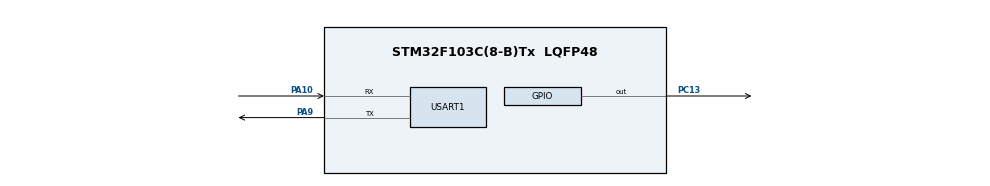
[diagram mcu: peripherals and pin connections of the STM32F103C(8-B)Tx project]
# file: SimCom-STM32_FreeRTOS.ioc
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Dma.Request0=USART1_TX
Dma.USART1_TX.0.Direction=DMA_MEMORY_TO_PERIPH
Dma.USART1_TX.0.Instance=DMA1_Channel4
Dma.USART1_TX.0.MemDataAlignment=DMA_MDATAALIGN_BYTE
Dma.USART1_TX.0.MemInc=DMA_MINC_ENABLE
Dma.USART1_TX.0.Mode=DMA_NORMAL
Dma.USART1_TX.0.PeriphDataAlignment=DMA_PDATAALIGN_BYTE
Dma.USART1_TX.0.PeriphInc=DMA_PINC_DISABLE
Dma.USART1_TX.0.Priority=DMA_PRIORITY_LOW
FREERTOS.HEAP_NUMBER=1
FREERTOS.Mutexes01=sl_send_lock;dl_send_lock;ph_send_lock
FREERTOS.Tasks01=defaultTask,0,256,StartDefaultTask,Default,NULL,Dynamic,NULL,NULL;sendTask,0,256,StartSendTask,As external,NULL,Dynamic,NULL,NULL;receiveTask,0,256,StartReceiveTask,As external,NULL,Dynamic,NULL,NULL
FREERTOS.configMINIMAL_STACK_SIZE=256
FREERTOS.configTOTAL_HEAP_SIZE=4808
FREERTOS.configUSE_PREEMPTION=0
Mcu.Family=STM32F1
Mcu.Name=STM32F103C(8-B)Tx
Mcu.Package=LQFP48
NVIC.DMA1_Channel4_IRQn=true\:5\:0\:false\:false\:true\:true
NVIC.PriorityGroup=NVIC_PRIORITYGROUP_4
NVIC.TIM1_UP_IRQn=true\:0\:0\:false\:false\:true\:false
NVIC.TimeBase=TIM1_UP_IRQn
NVIC.TimeBaseIP=TIM1
NVIC.USART1_IRQn=true\:5\:0\:false\:false\:true\:true
PA10.Mode=Multiprocessor_communication
PA10.Signal=USART1_RX
PA9.Mode=Multiprocessor_communication
PA9.Signal=USART1_TX
PC13-TAMPER-RTC.Signal=GPIO_Output
PD0-OSC_IN.Mode=HSE-External-Oscillator
PD0-OSC_IN.Signal=RCC_OSC_IN
PD1-OSC_OUT.Mode=HSE-External-Oscillator
PD1-OSC_OUT.Signal=RCC_OSC_OUT
ProjectManager.HeapSize=0x200
ProjectManager.StackSize=0x400
ProjectManager.TargetToolchain=SW4STM32
RCC.APB1Freq_Value=8000000
RCC.APB2Freq_Value=8000000
USART1.VirtualMode=VM_ASYNC
VP_FREERTOS_VS_ENABLE.Mode=Enabled
VP_SYS_VS_ND.Mode=No_Debug
VP_SYS_VS_tim1.Mode=TIM1
board=SimCom-STM32_FreeRTOS

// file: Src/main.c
/**
  ******************************************************************************
  * File Name          : main.c
  * Description        : Main program body
  ******************************************************************************
  * This notice applies to any and all portions of this file
  * that are not between comment pairs USER CODE BEGIN and
  * USER CODE END. Other portions of this file, whether
  * inserted by the user or by software development tools
  * are owned by their respective copyright owners.
  *
  * Copyright (c) 2017 STMicroelectronics International N.V.
  * All rights reserved.
  *
  * Redistribution and use in source and binary forms, with or without
  * modification, are permitted, provided that the following conditions are met:
  *
  * 1. Redistribution of source code must retain the above copyright notice,
  *    this list of conditions and the following disclaimer.
  * 2. Redistributions in binary form must reproduce the above copyright notice,
  *    this list of conditions and the following disclaimer in the documentation
  *    and/or other materials provided with the distribution.
  * 3. Neither the name of STMicroelectronics nor the names of other
  *    contributors to this software may be used to endorse or promote products
  *    derived from this software without specific written permission.
  * 4. This software, including modifications and/or derivative works of this
  *    software, must execute solely and exclusively on microcontroller or
  *    microprocessor devices manufactured by or for STMicroelectronics.
  * 5. Redistribution and use of this software other than as permitted under
  *    this license is void and will automatically terminate your rights under
  *    this license.
  *
  * THIS SOFTWARE IS PROVIDED BY STMICROELECTRONICS AND CONTRIBUTORS "AS IS"
  * AND ANY EXPRESS, IMPLIED OR STATUTORY WARRANTIES, INCLUDING, BUT NOT
  * LIMITED TO, THE IMPLIED WARRANTIES OF MERCHANTABILITY, FITNESS FOR A
  * PARTICULAR PURPOSE AND NON-INFRINGEMENT OF THIRD PARTY INTELLECTUAL PROPERTY
  * RIGHTS ARE DISCLAIMED TO THE FULLEST EXTENT PERMITTED BY LAW. IN NO EVENT
  * SHALL STMICROELECTRONICS OR CONTRIBUTORS BE LIABLE FOR ANY DIRECT, INDIRECT,
  * INCIDENTAL, SPECIAL, EXEMPLARY, OR CONSEQUENTIAL DAMAGES (INCLUDING, BUT NOT
  * LIMITED TO, PROCUREMENT OF SUBSTITUTE GOODS OR SERVICES; LOSS OF USE, DATA,
  * OR PROFITS; OR BUSINESS INTERRUPTION) HOWEVER CAUSED AND ON ANY THEORY OF
  * LIABILITY, WHETHER IN CONTRACT, STRICT LIABILITY, OR TORT (INCLUDING
  * NEGLIGENCE OR OTHERWISE) ARISING IN ANY WAY OUT OF THE USE OF THIS SOFTWARE,
  * EVEN IF ADVISED OF THE POSSIBILITY OF SUCH DAMAGE.
  *
  ******************************************************************************
  */
#include "main.h"
#include "stm32f1xx_hal.h"
#include "cmsis_os.h"

/* USER CODE BEGIN Includes */
#include "SimCom.h"

/* USER CODE END Includes */

UART_HandleTypeDef huart1;
DMA_HandleTypeDef hdma_usart1_tx;

osThreadId defaultTaskHandle;
osThreadId sendTaskHandle;
osThreadId receiveTaskHandle;
osMutexId sl_send_lockHandle;
osMutexId dl_send_lockHandle;
osMutexId ph_send_lockHandle;

/* USER CODE BEGIN PV */
/* Private variables ---------------------------------------------------------*/

/* USER CODE END PV */

void SystemClock_Config(void);
static void MX_GPIO_Init(void);
static void MX_DMA_Init(void);
static void MX_USART1_UART_Init(void);
void StartDefaultTask(void const * argument);
extern void StartSendTask(void const * argument);
extern void StartReceiveTask(void const * argument);

/* USER CODE BEGIN PFP */
/* Private function prototypes -----------------------------------------------*/

/* USER CODE END PFP */

int main(void)
{

  /* MCU Configuration----------------------------------------------------------*/

  /* Reset of all peripherals, Initializes the Flash interface and the Systick. */
  HAL_Init();

  /* Configure the system clock */
  SystemClock_Config();

  /* Initialize all configured peripherals */
  MX_GPIO_Init();
  MX_DMA_Init();
  MX_USART1_UART_Init();

  /* USER CODE BEGIN 2 */
  simcom_init(&huart1);

  /* USER CODE END 2 */

  /* Create the mutex(es) */
  /* definition and creation of sl_send_lock */
  osMutexDef(sl_send_lock);
  sl_send_lockHandle = osMutexCreate(osMutex(sl_send_lock));

  /* definition and creation of dl_send_lock */
  osMutexDef(dl_send_lock);
  dl_send_lockHandle = osMutexCreate(osMutex(dl_send_lock));

  /* definition and creation of ph_send_lock */
  osMutexDef(ph_send_lock);
  ph_send_lockHandle = osMutexCreate(osMutex(ph_send_lock));

  /* Create the thread(s) */
  /* definition and creation of defaultTask */
  osThreadDef(defaultTask, StartDefaultTask, osPriorityNormal, 0, 256);
  defaultTaskHandle = osThreadCreate(osThread(defaultTask), NULL);

  /* definition and creation of sendTask */
  osThreadDef(sendTask, StartSendTask, osPriorityNormal, 0, 256);
  sendTaskHandle = osThreadCreate(osThread(sendTask), NULL);

  /* definition and creation of receiveTask */
  osThreadDef(receiveTask, StartReceiveTask, osPriorityNormal, 0, 256);
  receiveTaskHandle = osThreadCreate(osThread(receiveTask), NULL);

  /* Start scheduler */
  osKernelStart();

  /* We should never get here as control is now taken by the scheduler */

  /* Infinite loop */
  while (1)
  {

  }

}

/** System Clock Configuration
*/
void SystemClock_Config(void)
{

  RCC_OscInitTypeDef RCC_OscInitStruct;
  RCC_ClkInitTypeDef RCC_ClkInitStruct;

    /**Initializes the CPU, AHB and APB busses clocks
    */
  RCC_OscInitStruct.OscillatorType = RCC_OSCILLATORTYPE_HSI;
  RCC_OscInitStruct.HSIState = RCC_HSI_ON;
  RCC_OscInitStruct.HSICalibrationValue = 16;
  RCC_OscInitStruct.PLL.PLLState = RCC_PLL_NONE;
  if (HAL_RCC_OscConfig(&RCC_OscInitStruct) != HAL_OK)
  {
    _Error_Handler(__FILE__, __LINE__);
  }

    /**Initializes the CPU, AHB and APB busses clocks
    */
  RCC_ClkInitStruct.ClockType = RCC_CLOCKTYPE_HCLK|RCC_CLOCKTYPE_SYSCLK
                              |RCC_CLOCKTYPE_PCLK1|RCC_CLOCKTYPE_PCLK2;
  RCC_ClkInitStruct.SYSCLKSource = RCC_SYSCLKSOURCE_HSI;
  RCC_ClkInitStruct.AHBCLKDivider = RCC_SYSCLK_DIV1;
  RCC_ClkInitStruct.APB1CLKDivider = RCC_HCLK_DIV1;
  RCC_ClkInitStruct.APB2CLKDivider = RCC_HCLK_DIV1;

  if (HAL_RCC_ClockConfig(&RCC_ClkInitStruct, FLASH_LATENCY_0) != HAL_OK)
  {
    _Error_Handler(__FILE__, __LINE__);
  }

    /**Configure the Systick interrupt time
    */
  HAL_SYSTICK_Config(HAL_RCC_GetHCLKFreq()/1000);

    /**Configure the Systick
    */
  HAL_SYSTICK_CLKSourceConfig(SYSTICK_CLKSOURCE_HCLK);

  /* SysTick_IRQn interrupt configuration */
  HAL_NVIC_SetPriority(SysTick_IRQn, 15, 0);
}

/* USART1 init function */
static void MX_USART1_UART_Init(void)
{

  huart1.Instance = USART1;
  huart1.Init.BaudRate = 115200;
  huart1.Init.WordLength = UART_WORDLENGTH_8B;
  huart1.Init.StopBits = UART_STOPBITS_1;
  huart1.Init.Parity = UART_PARITY_NONE;
  huart1.Init.Mode = UART_MODE_TX_RX;
  huart1.Init.HwFlowCtl = UART_HWCONTROL_NONE;
  huart1.Init.OverSampling = UART_OVERSAMPLING_16;
  if (HAL_MultiProcessor_Init(&huart1, 0, UART_WAKEUPMETHOD_IDLELINE) != HAL_OK)
  {
    _Error_Handler(__FILE__, __LINE__);
  }

}

static void MX_DMA_Init(void)
{
  /* DMA controller clock enable */
  __HAL_RCC_DMA1_CLK_ENABLE();

  /* DMA interrupt init */
  /* DMA1_Channel4_IRQn interrupt configuration */
  HAL_NVIC_SetPriority(DMA1_Channel4_IRQn, 5, 0);
  HAL_NVIC_EnableIRQ(DMA1_Channel4_IRQn);

}

/** Configure pins as
        * Analog
        * Input
        * Output
        * EVENT_OUT
        * EXTI
*/
static void MX_GPIO_Init(void)
{

  GPIO_InitTypeDef GPIO_InitStruct;

  /* GPIO Ports Clock Enable */
  __HAL_RCC_GPIOC_CLK_ENABLE();
  __HAL_RCC_GPIOD_CLK_ENABLE();
  __HAL_RCC_GPIOA_CLK_ENABLE();

  /*Configure GPIO pin Output Level */
  HAL_GPIO_WritePin(GPIOC, GPIO_PIN_13, GPIO_PIN_RESET);

  /*Configure GPIO pin : PC13 */
  GPIO_InitStruct.Pin = GPIO_PIN_13;
  GPIO_InitStruct.Mode = GPIO_MODE_OUTPUT_PP;
  GPIO_InitStruct.Speed = GPIO_SPEED_FREQ_LOW;
  HAL_GPIO_Init(GPIOC, &GPIO_InitStruct);

}

/* StartDefaultTask function */
void StartDefaultTask(void const * argument)
{

  /* USER CODE BEGIN 5 */

  /* Infinite loop */
  for(;;)
  {
	  sl_send(0,0,"test", 4);

	  HAL_GPIO_WritePin(GPIOC, GPIO_PIN_13, 0);
	  osDelay(500);
	  HAL_GPIO_WritePin(GPIOC, GPIO_PIN_13, 1);
	  osDelay(500);
  }
  /* USER CODE END 5 */
}

void HAL_TIM_PeriodElapsedCallback(TIM_HandleTypeDef *htim)
{
  if (htim->Instance == TIM1) {
    HAL_IncTick();
  }
}

void _Error_Handler(char * file, int line)
{
  while(1)
  {
  }
}

/************************ (C) COPYRIGHT STMicroelectronics *****END OF FILE****/
